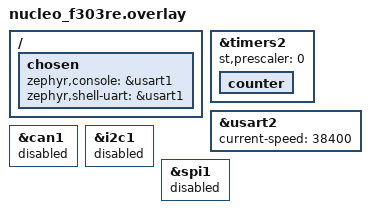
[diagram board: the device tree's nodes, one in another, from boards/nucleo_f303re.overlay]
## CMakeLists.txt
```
# SPDX-License-Identifier: Apache-2.0

cmake_minimum_required(VERSION 3.20.0)
find_package(Zephyr REQUIRED HINTS $ENV{ZEPHYR_BASE})
project(counter)

FILE(GLOB app_sources src/*.c src/test_threads/*.c)
target_sources(app PRIVATE ${app_sources})


set(CMAKE_C_FLAGS "${CMAKE_C_FLAGS} -Os -g0")


if(DEFINED DEBUG_PRINTF)
  zephyr_compile_definitions(DEBUG_PRINTF=${DEBUG_PRINTF})
endif()
if(DEFINED SAME_PRIO)
  zephyr_compile_definitions(SAME_PRIO)
endif()
if(DEFINED FORKS)
  zephyr_compile_definitions(FORKS=${FORKS})
endif()

target_include_directories(app PRIVATE ${ZEPHYR_BASE}/include/zephyr/portability inc)
```

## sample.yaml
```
sample:
  name: Blinky Sample
tests:
  sample.basic.blinky:
    tags:
      - LED
      - gpio
      - drivers
      - counter
    depends_on: counter
    harness: led
    integration_platforms:
      - frdm_k64f
```

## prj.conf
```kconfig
CONFIG_ASSERT=y
CONFIG_GPIO=y
CONFIG_COUNTER=y
CONFIG_ASSERT_LEVEL=2
CONFIG_CMSIS_RTOS_V1=y
CONFIG_NUM_PREEMPT_PRIORITIES=9
CONFIG_HEAP_MEM_POOL_SIZE=256
CONFIG_THREAD_NAME=y
CONFIG_THREAD_STACK_INFO=y
CONFIG_THREAD_MONITOR=y
CONFIG_INIT_STACKS=y
CONFIG_POLL=y
CONFIG_SCHED_SCALABLE=y
CONFIG_THREAD_CUSTOM_DATA=y
CONFIG_CMSIS_THREAD_MAX_STACK_SIZE=1024
CONFIG_SERIAL=y
CONFIG_SPI=n
CONFIG_SYS_CLOCK_HW_CYCLES_PER_SEC=72000000
CONFIG_MAIN_STACK_SIZE=2048
CONFIG_IDLE_STACK_SIZE=1024
CONFIG_SYSTEM_WORKQUEUE_STACK_SIZE=2048
CONFIG_UART_INTERRUPT_DRIVEN=y
CONFIG_PRINTK=n
CONFIG_BOOT_BANNER=n
CONFIG_DEBUG=n
CONFIG_UART_CONSOLE=n
CONFIG_SYS_CLOCK_TICKS_PER_SEC=1000
CONFIG_TIMESLICING=y
CONFIG_TIMESLICE_SIZE=1
CONFIG_TIMESLICE_PRIORITY=0
```

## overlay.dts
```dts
/dts-v1/;
/plugin/;

/ {
    fragment@0 {
        target-path = "/";
        __overlay__ {
            timers2: timers@40000000 {
                st,prescaler = <0x100>; // Modified prescaler value
            };
        };
    };
};
```

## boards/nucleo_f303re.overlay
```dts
/ {
    chosen {
        zephyr,console = &usart1;
        zephyr,shell-uart = &usart1;
    };
};

&timers2 {
	st,prescaler = <0>;
	counter {
		status = "okay";
	};
};

&usart2 {
	current-speed = <38400>;
};

&can1 {
	status = "disabled";
};

&i2c1 {
	status = "disabled";
};

&spi1 {
	status = "disabled";
};
```

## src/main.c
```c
/*
 * Copyright (c) 2016 Intel Corporation
 *
 * SPDX-License-Identifier: Apache-2.0
 */

#include <stdio.h>
#include <zephyr/kernel.h>
#include <zephyr/drivers/gpio.h>
#include <zephyr/kernel.h>
#include <zephyr/sys/__assert.h>
#include <threads_inc.h>
// #include <zephyr/sys/printk.h>

struct counter_top_cfg top_cfg;
uint32_t values[MAX_THREADS][MAX_TEST_PER_THREAD];
int start_flag;
osMutexId mutexHandle;
osMessageQId queueHandle;

const struct device *counter_dev;
struct counter_alarm_cfg alarm_cfg;
const struct device *uart2;

// #define TESTING_BARE_METAL 1

#define TIMER         DT_INST(0, st_stm32_counter)
/* 1000 msec = 1 sec */
#define SLEEP_TIME_MS 1000

/* The devicetree node identifier for the "led0" alias. */
#define LED0_NODE DT_ALIAS(led0)

/*
 * A build error on this line means your board is unsupported.
 * See the sample documentation for information on how to fix this.
 */
static const struct gpio_dt_spec led = GPIO_DT_SPEC_GET(LED0_NODE, gpios);

uint32_t get_time()
{
	uint32_t temp;
	counter_get_value(counter_dev, &temp);
	return temp;
}
int main(void)
{

	counter_dev = DEVICE_DT_GET(TIMER);
	uart2 = DEVICE_DT_GET(DT_NODELABEL(usart2));
	gpio_pin_toggle_dt(&led);

	if (!device_is_ready(uart2)) {

		return 1;
	}

	if (!device_is_ready(led.port)) {

		return 1;
	}

	int ret = gpio_pin_configure_dt(&led, GPIO_OUTPUT_ACTIVE);
	if (ret < 0) {

		return 1;
	}

	if (!device_is_ready(counter_dev)) {
		return 1;
	}

	top_cfg.ticks = counter_us_to_ticks(counter_dev, 0xFFFFFFFF);
	top_cfg.callback = NULL;
	top_cfg.user_data = NULL;
	top_cfg.flags = 0;

#ifndef TESTING_BARE_METAL
	osThreadDef(mainThread, osPriorityNormal, 1, 1024);
	osThreadCreate(osThread(mainThread), NULL);
#else
	ret = counter_start(counter_dev);
	if (ret != 0) {
		return 1;
	}
	counter_set_top_value(counter_dev, &top_cfg);

	int i = 0;
	uint32_t time[101];

	// First ten is to check how much does read take

	counter_get_value(counter_dev, &time[i++]);
	counter_get_value(counter_dev, &time[i++]);
	counter_get_value(counter_dev, &time[i++]);
	counter_get_value(counter_dev, &time[i++]);
	counter_get_value(counter_dev, &time[i++]);

	while (1) {
		counter_get_value(counter_dev, &time[i++]);
		if (i == 100) {
			break;
		}
	}

	counter_get_value(counter_dev, &time[i++]);
	counter_stop(counter_dev);

	char text[10];

	for (int j = 0; j < i - 1; j++) {
		snprintf(text, sizeof(text), "%lu", time[j + 1] - time[j]);
		uart_poll_out(uart2, text[0]);
		uart_poll_out(uart2, text[1]);
		uart_poll_out(uart2, ' ');
	}

#endif // !TESTING_BARE_METAL

	return 0;
}
```

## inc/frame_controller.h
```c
/**
 * @file frame_controller.h
 * @author Krzysztof Bortnowski (krzysztof.bortnowski@sesto.pl)
 * @brief
 * @version 0.1
 * @date 2024-04-11
 *
 * @copyright Copyright (c) 2024
 *
 */

#include "stdlib.h"
#include "inttypes.h"

#define MAX_ARGS_COMMAND_FRAME 4
#define MAX_ARGS_SCORE_FRAME   400
#define COMMAND_FRAME_SIZE     (5 + MAX_ARGS_COMMAND_FRAME)
#define SCORE_FRAME_SIZE       (6 + MAX_ARGS_SCORE_FRAME)

typedef enum {
	CMD_TASK_FORCE_SWITCH = 0,
	CMD_TASK_SWITCH,
	CMD_SEMAPHORE,
	CMD_QUEUE,
	CMD_COMMAND_NO
} commands_em;

#define ERR_FRM_NO_START      -1
#define ERR_FRM_CRC           -2
#define ERR_FRM_WRONG_COMMAND -3
#define ERR_FRM_TOO_MANY_ARGS -4

/**
 * @brief Decodes with CRC Check
 *
 * @param frame
 * @param command
 * @param arg_count
 * @param args
 * @return int
 */
int DecodeCommandFrame(uint8_t *frame, uint8_t *command, uint8_t *arg_count, uint8_t *args);

/**
 * @brief Codes frame with CRC
 *
 * @param frame
 * @param command
 * @param arg_count
 * @param args
 * @return ERR_FRM
 */
int CodeScoreFrame(uint8_t *frame, uint8_t command, uint16_t arg_count, uint8_t *args);
```

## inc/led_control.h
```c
#ifndef LED_CONTROL_H
#define LED_CONTROL_H

#include <zephyr/drivers/gpio.h>

void led_init(void);
void led_toggle(void);

#endif // LED_CONTROL_H
```

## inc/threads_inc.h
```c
/**
 * @file threads.h
 * @author Krzysztof Bortnowski (krzysztof.bortnowski@sesto.pl)
 * @brief
 * @version 0.1
 * @date 2024-04-10
 *
 * @copyright Copyright (c) 2024
 *
 */

#ifndef THREADS_INC_H_
#define THREADS_INC_H_

#define MAX_THREADS         22
#define MAX_TEST_PER_THREAD 80

#include <zephyr/device.h>
#include "cmsis_os.h"
#include <zephyr/drivers/counter.h>
#include <zephyr/drivers/uart.h>

void mainThread(void const *argument);
void forceSwitchThread(void const *argument);
void switchThread(void const *argument);
void semaphoreThread(void const *argument);
void queueTransmitterThread(void const *argument);
void queueRecieverThread(void const *argument);
int uart_receive(uint8_t *buffer, size_t length, int timeout);
int uart_transmit(const uint8_t *buffer, size_t length, int timeout);
uint32_t get_time();

extern osMutexId mutexHandle;
extern osMessageQId queueHandle;

extern const struct device *counter_dev;
extern const struct device *uart2;

extern uint32_t values[MAX_THREADS][MAX_TEST_PER_THREAD];
extern int start_flag;

extern struct counter_top_cfg top_cfg;
#endif // THREADS_INC_H_
```

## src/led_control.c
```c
#include "led_control.h"
#include <zephyr/kernel.h>
#include <zephyr/device.h>
#include <zephyr/devicetree.h>
#include <zephyr/drivers/gpio.h>
#include <zephyr/sys/__assert.h>

#define LED0_NODE DT_ALIAS(led0)

static const struct gpio_dt_spec led = GPIO_DT_SPEC_GET(LED0_NODE, gpios);

void led_init(void)
{
	if (!device_is_ready(led.port)) {
		__ASSERT(false, "LED device not ready");
		return;
	}

	int ret = gpio_pin_configure_dt(&led, GPIO_OUTPUT_ACTIVE);
	if (ret < 0) {
		__ASSERT(false, "Failed to configure LED pin");
		return;
	}
}

void led_toggle(void)
{
	gpio_pin_toggle_dt(&led);
}
```

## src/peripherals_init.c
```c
#include <zephyr/drivers/timer/system_timer.h>
#include <zephyr/drivers/uart.h>
#include <zephyr/kernel.h>

#define TIMER_NODE DT_ALIAS(timer1)
#define UART_NODE  DT_ALIAS(uart2)

static const struct device *timer_dev;
static const struct device *uart_dev;
void timer_init(void)
{
	// timer_dev = device_get_binding(DT_LABEL(TIMER_NODE));
	// if (!timer_dev)
	// {
	//     printk("Error: could not find %s\n", DT_LABEL(TIMER_NODE));
	//     return;
	// }

	// // Timer configuration
	// timer_configured_set(timer_dev, TIMER_CFG_DCS | TIMER_CFG_PCS);
}

void uart_init(void)
{
	// uart_dev = device_get_binding(DT_LABEL(UART_NODE));
	// if (!uart_dev) {
	// 	printk("Error: could not find %s\n", DT_LABEL(UART_NODE));
	// 	return;
	// }

	// UART configuration
	// uart_configure(uart_dev, &uart_cfg);
}
```

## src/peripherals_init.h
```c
#ifndef PERYHERIALS_INIT_H_
#define PERYHERIALS_INIT_H_

void timer_init(void);
void uart_init(void);

#endif // PERYHERIALS_INIT_H_
```

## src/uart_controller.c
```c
#include <threads_inc.h>
#include <zephyr/kernel.h>

static struct k_msgq uart_msgq;
static uint8_t uart_msgq_buffer[64 * sizeof(uint8_t)];

static void uart_rx_callback(const struct device *uart_dev, void *user_data)
{
	uint8_t c;

	if (!uart_irq_update(uart_dev)) {
		return;
	}

	if (!uart_irq_rx_ready(uart_dev)) {
		return;
	}

	while (uart_fifo_read(uart_dev, &c, 1) == 1) {
		k_msgq_put(&uart_msgq, &c, K_NO_WAIT);
	}
}

int uart_receive(uint8_t *buffer, size_t length, int timeout)
{
	k_msgq_init(&uart_msgq, uart_msgq_buffer, sizeof(uint8_t), 64);

	// Enable UART and set callback
	uart_irq_callback_user_data_set(uart2, uart_rx_callback, NULL);
	uart_irq_rx_enable(uart2);

	for (size_t i = 0; i < length; i++) {
		if (k_msgq_get(&uart_msgq, &buffer[i], K_MSEC(timeout)) != 0) {
			// Disable UART receive
			uart_irq_rx_disable(uart2);
			uart_irq_callback_user_data_set(uart2, NULL, NULL);
			return -1; // Timeout occurred
		}
	}
	// Disable UART receive
	uart_irq_rx_disable(uart2);
	uart_irq_callback_user_data_set(uart2, NULL, NULL);

	return 0; // Reception successful
}

int uart_transmit(const uint8_t *buffer, size_t length, int timeout)
{
	volatile size_t i = 0;
	for (i = 0; i < length; i++) {
		uart_poll_out(uart2, buffer[i]);
	}
	return 0;
}
```
